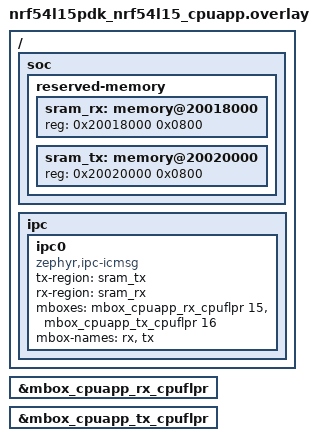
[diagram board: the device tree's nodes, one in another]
/*
 * Copyright (c) 2024 Nordic Semiconductor ASA
 *
 * SPDX-License-Identifier: Apache-2.0
 */

/ {
	soc {
		reserved-memory {
			#address-cells = <1>;
			#size-cells = <1>;

			sram_rx: memory@20018000 {
				reg = <0x20018000 0x0800>;
			};

			sram_tx: memory@20020000 {
				reg = <0x20020000 0x0800>;
			};
		};
	};

	ipc {
		ipc0: ipc0 {
			compatible = "zephyr,ipc-icmsg";
			tx-region = <&sram_tx>;
			rx-region = <&sram_rx>;
			mboxes = <&mbox_cpuapp_rx_cpuflpr 15>, <&mbox_cpuapp_tx_cpuflpr 16>;
			mbox-names = "rx", "tx";
			status = "okay";
		};
	};
};

&mbox_cpuapp_rx_cpuflpr {
	status = "okay";
};

&mbox_cpuapp_tx_cpuflpr {
	status = "okay";
};
